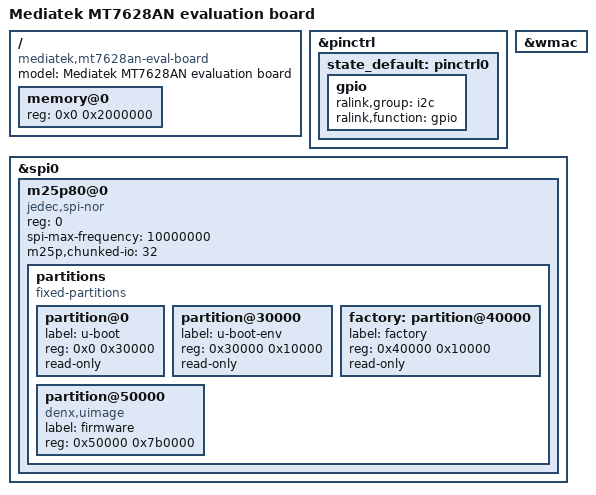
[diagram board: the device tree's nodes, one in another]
/dts-v1/;

#include "mt7628an.dtsi"

/ {
	compatible = "mediatek,mt7628an-eval-board", "mediatek,mt7628an-soc";
	model = "Mediatek MT7628AN evaluation board";

	memory@0 {
		device_type = "memory";
		reg = <0x0 0x2000000>;
	};
};

&pinctrl {
	state_default: pinctrl0 {
		gpio {
			ralink,group = "i2c";
			ralink,function = "gpio";
		};
	};
};

&wmac {
	status = "okay";
};

&spi0 {
	status = "okay";

	m25p80@0 {
		compatible = "jedec,spi-nor";
		reg = <0>;
		spi-max-frequency = <10000000>;
		m25p,chunked-io = <32>;

		partitions {
			compatible = "fixed-partitions";
			#address-cells = <1>;
			#size-cells = <1>;

			partition@0 {
				label = "u-boot";
				reg = <0x0 0x30000>;
				read-only;
			};

			partition@30000 {
				label = "u-boot-env";
				reg = <0x30000 0x10000>;
				read-only;
			};

			factory: partition@40000 {
				label = "factory";
				reg = <0x40000 0x10000>;
				read-only;
			};

			partition@50000 {
				compatible = "denx,uimage";
				label = "firmware";
				reg = <0x50000 0x7b0000>;
			};
		};
	};
};

&wmac {
	status = "okay";
};
